# RN821X_RN721X_SOC_V2 register map
File version: v1.0.7
CPU: CM0 r0p0, little endian, no MPU, no FPU, 3 interrupt priority bits
Registers are 32-bit, read-write, reset 0x0 unless marked. A register's access mark holds for its fields unless they carry their own. Offsets are from the block's base; [hi:lo] are bit positions; {n}, {i} and the like mark numbered series; 'fields as' and 'values as' point back to an identical list.

## GPIO
Base 0x50000000
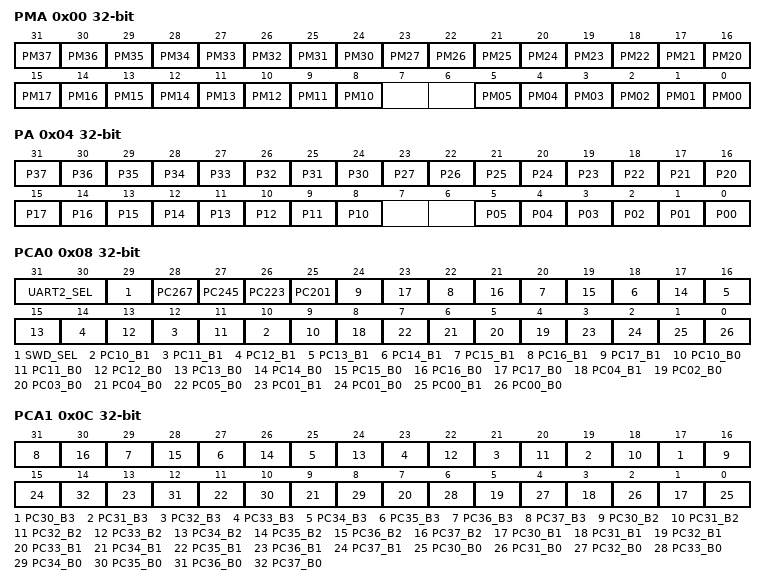
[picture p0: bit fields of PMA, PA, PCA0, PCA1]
0x00 PMA — port A mode register
  [all] fields
    0=OUT (use as output mode); 1=IN (use as input mode)
  [31] PM37 — P37 input(1)/output(0) mode state bi
  [30] PM36 — P36 input(1)/output(0) mode state bit
  [n-6] PM{n} (n=30..35) — P{n} input(1)/output(0) mode selection bit
  [n-4] PM{n} (n=20..27) — P{n} input(1)/output(0) mode selection bit
  [n-2] PM{n} (n=10..17) — P{n} input(1)/output(0) mode selection bit
  [n] PM{n:02} (n=0..5) — P{n:02} input(1)/output(0) mode selection bit
0x04 PA — port A data register
  [31] P37 ro — port A P37 data bit
  [30] P36 ro — port A P36 data bit
  [n-6] P{n} (n=30..35) — port A P{n} data bit
  [n-4] P{n} (n=20..27) — port A P{n} data bit
  [n-2] P{n} (n=10..17) — port A P{n} data bit
  [n] P{n:02} (n=0..5) — port A P{n:02} data bit
0x08 PCA0 — port A mode config register 0
  [31:30] UART2_SEL — UART2 selection bits
    0=PC245 (select P24/P25 as UART2, when P24/P25 PC245 properly cfg as UART2); 1=PC0_1 (select P00/P01 as UART2, when P00/P01 PC00 PC01 properly cfg as UART2); 2=PC223 (select P22/P23 as UART2, when P22/P23 PC223 properly cfg as UART2); 3=PC267 (select P26/P27 as UART2, when P26/P27 PC267 properly cfg as UART2)
  [29] SWD_SEL — SWD selection bit
    0=OTH (when PCA3.PC245(PCA3[20]) = 0, P24 P25 function define by PCA0.PCA0_PC245); 1=P245 (when PCA3.PC245(PCA3[20]) = 0, use P24 as SWDCLK and P25 as SWDIO)
  [28] PC267 — P26 and P27 mode cfg bit
    0=IO (P26 and P27 use as general IO, available when PCA3.PC267(PCA3[27]) = 0); 1=UART3 (P26(RX3) and P27(TX3) use as UART3, available when PCA3.PC267(PCA3[27]) = 0)
  [27] PC245 — P24 and P25 mode cfg bit
    0=IO (P24 and P25 use as general IO, available when PCA3.PC245(PCA3[20]) = 0 and PCA0.SWD_SEL(PCA0[29]) =0); 1=UART2 (P24(RX2) and P25(TX2) use as UART2, available when PCA3.PC245(PCA3[20]) = 0 and PCA0.SWD_SEL(PCA0[29]) =0)
  [26] PC223 — P22 and P23 mode cfg bit
    0=IO (P22 and P23 use as general IO, available when PCA3.PC223(PCA3[13]) = 0); 1=UART1 (P22(RX1) and P23(TX1) use as UART1, available when PCA3.PC223(PCA3[13]) = 0)
  [25] PC201 — P20 and P21 mode cfg bit
    0=IO (P20 and P21 use as general IO, available when PCA3.PC201(PCA3[6]) = 0); 1=UART0 (P20(RX0) and P21(TX0) use as UART0, available when PCA3.PC201(PCA3[6]) = 0)
  [2n-10] PC{n}_B1 (n=10..17) — PC{n} mode cfg bit1, detail info please read manual PCA0.PC{n}(PCA0[{2n-10}:{2n-11}])
  [2n-11] PC{n}_B0 (n=10..17) — PC{n} mode cfg bit0, detail info please read manual PCA0.PC{n}(PCA0[{2n-10}:{2n-11}])
  [8] PC04_B1 — PC04 mode cfg bit1, detail info please read manual PCA0.PC04(PCA0[6])
  [n+2] PC{n:02}_B0 (n=2..5) — PC{n:02} mode cfg bit0, detail info please read manual PCA0.PC{n:02}(PCA0[{n+2}])
  [3] PC01_B1 — PC01 mode cfg bit1, detail info please read manual PCA0.PC01(PCA0[3:2])
  [2] PC01_B0 — PC01 mode cfg bit0, detail info please read manual PCA0.PC01(PCA0[3:2])
  [1] PC00_B1 — PC00 mode cfg bit1, detail info please read manual PCA0.PC00(PCA0[1:0])
  [0] PC00_B0 — PC00 mode cfg bit0, detail info please read manual PCA0.PC00(PCA0[1:0])
0x0C PCA1 — port A mode config register 1
  [2n-43] PC{n}_B3 (n=30..37) — PC{n} mode cfg bit3, detail info please read manual PCA1.PC{n}(PCA1[{2n-59}:{2n-60}])
  [2n-44] PC{n}_B2 (n=30..37) — PC{n} mode cfg bit2, detail info please read manual PCA1.PC{n}(PCA1[{2n-59}:{2n-60}])
  [2n-59] PC{n}_B1 (n=30..37) — PC{n} mode cfg bit1, detail info please read manual PCA1.PC{n}(PCA1[{2n-59}:{2n-60}])
  [2n-60] PC{n}_B0 (n=30..37) — PC{n} mode cfg bit0, detail info please read manual PCA1.PC{n}(PCA1[{2n-59}:{2n-60}])
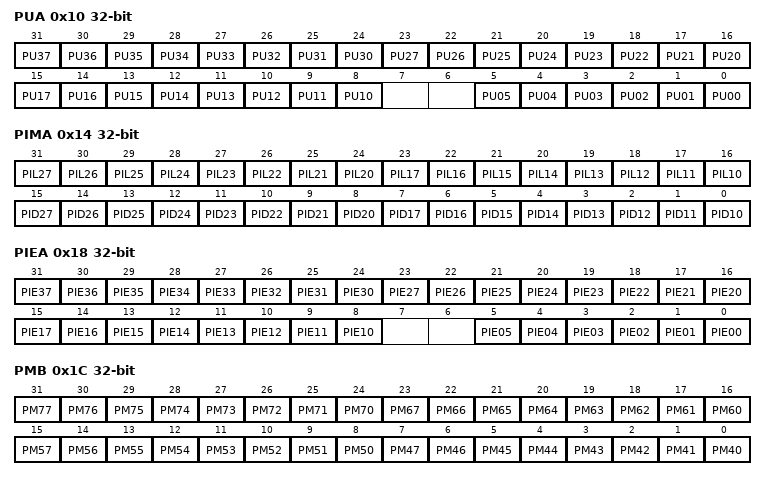
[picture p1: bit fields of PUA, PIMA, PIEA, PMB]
0x10 PUA — port A pull-up config register
  [all] fields
    0=NUL (do not pull-up); 1=PU (pull-up)
  [n-6] PU{n} (n=30..37) — P{n} pull up cfg bit (=0 do not pull up, =1 pull up)
  [n-4] PU{n} (n=20..27) — P{n} pull up cfg bit (=0 do not pull up, =1 pull up)
  [n-2] PU{n} (n=10..17) — P{n} pull up cfg bit (=0 do not pull up, =1 pull up)
  [n] PU{n:02} (n=0..5) — P{n:02} pull up cfg bit (=0 do not pull up, =1 pull up)
0x14 PIMA — port A input config register
  [n+4] PIL{n} (n=20..27) — P{n} input cfg bit
    0=CMOS (select as CMOS input mode, Vil=0.3VCC Vih = 0.7VCC); 1=TTL (select as TTL input mode, Vil=0.16VCC Vih = 0.4VCC)
  [n+6] PIL{n} (n=10..17) — P{n} input cfg bit
    values as PIL20
  [n-12] PID{n} (n=20..27) — P{n} output mode cfg bit
    0=NORM (select as normal output mode); 1=NCH (select as N channel open drain output)
  [n-10] PID{n} (n=10..17) — P{n} output mode cfg bit
    values as PID20
0x18 PIEA — port A input enable register
  [n-6] PIE{n} (n=30..37) — P{n} input disbale bit (=1 disable input, =0 enable input)
  [n-4] PIE{n} (n=20..27) — P{n} input disbale bit (=1 disable input, =0 enable input)
  [n-2] PIE{n} (n=10..17) — P{n} input disbale bit (=1 disable input, =0 enable input)
  [n] PIE{n:02} (n=1..5) — P{n:02} input disbale bit (=1 disable input, =0 enable input)
  [0] PIE00 — P00 input disbale bit (=1 disable input, =0 enable input)
    1=DIS (disable input); 0=EN (enable input)
0x1C PMB — port B mode register
  [n-46] PM{n} (n=70..77) — P{n} input/output cfg bit (=0 output mode, =1 input mode)
  [n-44] PM{n} (n=60..67) — P{n} input/output cfg bit (=0 output mode, =1 input mode)
  [n-42] PM{n} (n=50..57) — P{n} input/output cfg bit (=0 output mode, =1 input mode)
  [n-40] PM{n} (n=41..47) — P{n} input/output cfg bit (=0 output mode, =1 input mode)
  [0] PM40 — P40 input/output cfg bit (=0 output mode, =1 input mode)
    0=OUT (use as output mode); 1=IN (use as input mode)
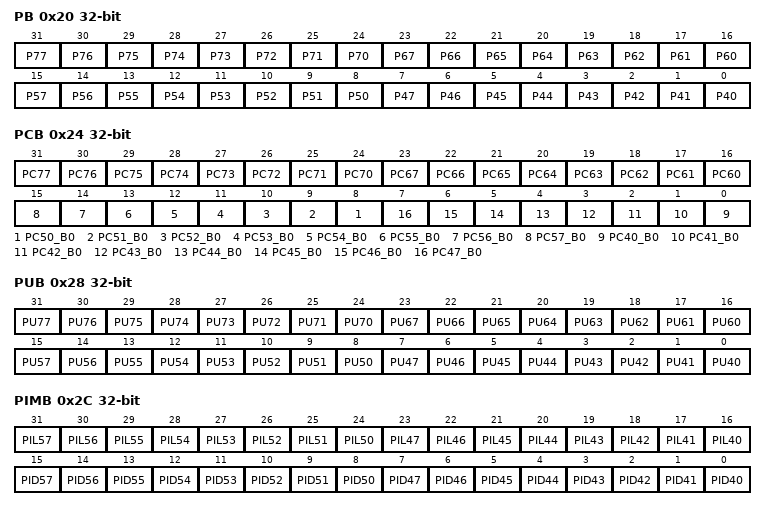
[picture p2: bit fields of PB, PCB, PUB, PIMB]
0x20 PB — port B data register
  [n-46] P{n} (n=70..77) — port B P{n} data bit
  [n-44] P{n} (n=60..67) — port B P{n} data bit
  [n-42] P{n} (n=50..57) — port B P{n} data bit
  [n-40] P{n} (n=40..47) — port B P{n} data bit
0x24 PCB — port B mode config register
  [n-46] PC{n} (n=70..77) — P{n} mode cfg bit
    0=IO (use as general IO); 1=LCD (use as LCD)
  [n-44] PC{n} (n=60..67) — P{n} mode cfg bit
    0=IO (use as general IO); 1=LCD (use as LCD)
  [n-42] PC{n}_B0 (n=50..57) — PC{n} mode cfg bit0, detail info please read manual PCB[{n-42}]
  [n-40] PC{n}_B0 (n=40..47) — PC{n} mode cfg bit0, detail info please read manual PCB[{n-40}]
0x28 PUB — port B pull-up/down config register
  [n-46] PU{n} (n=70..77) — P{n} pull-down enable bit (=1 enable pull-down, =0 do not enable pul down)
    0=NUL (do not pull-down); 1=DOWN (pull-down)
  [n-44] PU{n} (n=60..67) — P{n} pull-down enable bit (=1 enable pull-down, =0 do not enable pul down)
    0=NUL (do not pull-down); 1=DOWN (pull-down)
  [n-42] PU{n} (n=50..57) — P{n} pull-up enable bit (=1 enable pull-up, =0 do not enable pull up)
    0=NUL (do not pull-up); 1=UP (pull-up)
  [n-40] PU{n} (n=40..47) — P{n} pull-up enable bit (=1 enable pull-up, =0 do not enable pull up)
    0=NUL (do not pull-up); 1=UP (pull-up)
0x2C PIMB — port B input config register
  [n-26] PIL{n} (n=50..57) — P{n} input mode cfg bit
    values as PIMA.PIL20
  [n-24] PIL{n} (n=40..47) — P{n} input mode cfg bit
    values as PIMA.PIL20
  [n-42] PID{n} (n=50..57) — P{n} output mode cfg bit
    values as PIMA.PID20
  [n-40] PID{n} (n=40..47) — P{n} output mode cfg bit
    values as PIMA.PID20
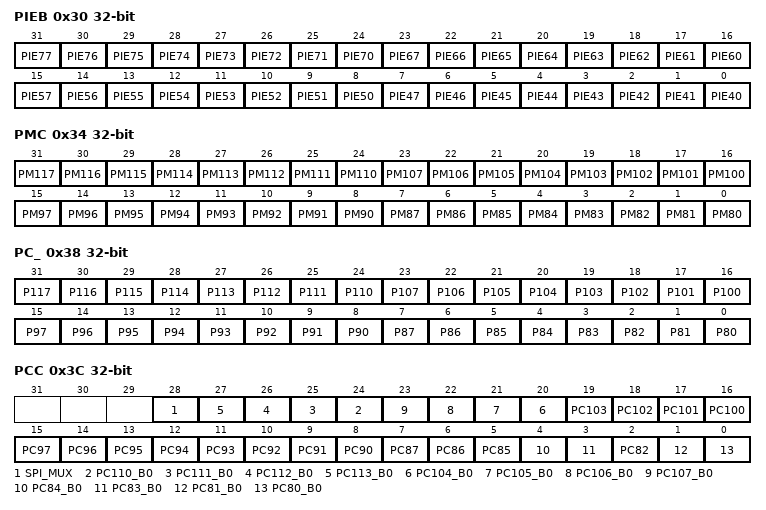
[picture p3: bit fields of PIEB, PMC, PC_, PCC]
0x30 PIEB — port B input enable register
  [all] fields
    1=DIS (do not use as input); 0=EN (use as input)
  [n-46] PIE{n} (n=70..77) — P{n} input disable bit (=1 disable input, =0 enable input)
  [n-44] PIE{n} (n=60..67) — P{n} input disable bit (=1 disable input, =0 enable input)
  [n-42] PIE{n} (n=50..57) — P{n} input disable bit (=1 disable input, =0 enable input)
  [n-40] PIE{n} (n=40..47) — P{n} input disable bit (=1 disable input, =0 enable input)
0x34 PMC — port C mode register
  [all] fields
    0=OUT (use as output mode); 1=IN (use as input mode)
  [n-86] PM{n} (n=110..117) — P{n} input/output cfg bit (=0 output mode, =1 input mode)
  [n-84] PM{n} (n=100..107) — P{n} input/output cfg bit (=0 output mode, =1 input mode)
  [n-82] PM{n} (n=90..97) — P{n} input/output cfg bit (=0 output mode, =1 input mode)
  [n-80] PM{n} (n=80..87) — P{n} input/output cfg bit (=0 output mode, =1 input mode)
0x38 PC_ — port C data register
  [n-86] P{n} (n=110..117) — port C P{n} data bit
  [n-84] P{n} (n=100..107) — port C P{n} data bit
  [n-82] P{n} (n=90..97) — port C P{n} data bit
  [n-80] P{n} (n=80..87) — port C P{n} data bit
0x3C PCC — port C mode config register
  [28] SPI_MUX — SPI0 pin defination bit
    0=P4 (select P50/P51/P46/P47 as SPI0); 1=P11 (select P110/P111/P112/P113 as SPI0)
  [n-86] PC{n}_B0 (n=110..113) — PC{n} mode cfg bit0, detail info please read manual PCC[{n-86}]
  [n-84] PC{n}_B0 (n=104..107) — PC{n} mode cfg bit0, detail info please read manual PCC[{n-84}]
  [n-84] PC{n} (n=100..103) — PC{n} mode cfg bit
    0=IO (select as general IO); 1=LCD (select as LCD)
  [n-82] PC{n} (n=90..97) — PC{n} mode cfg bit
    0=IO (select as general IO); 1=LCD (select as LCD)
  [7] PC87 — PC87 mode cfg bit
    0=IO (select as general IO); 1=LCD (select as LCD)
  [6] PC86 — PC86 mode cfg bit
    0=IO (select as general IO); 1=LCD (select as LCD)
  [5] PC85 — PC85 mode cfg bit
    0=IO (select as general IO); 1=LCD (select as LCD)
  [4] PC84_B0 — PC84 mode cfg bit0, detail info please read manual PCC[4]
  [3] PC83_B0 — PC83 mode cfg bit0, detail info please read manual PCC[3]
  [2] PC82 — PC82 mode cfg bit
    0=IO (select as general IO); 1=LCD (select as LCD)
  [1] PC81_B0 — PC81 mode cfg bit0, detail info please read manual PCC[1]
  [0] PC80_B0 — PC80 mode cfg bit0, detail info please read manual PCC[0]
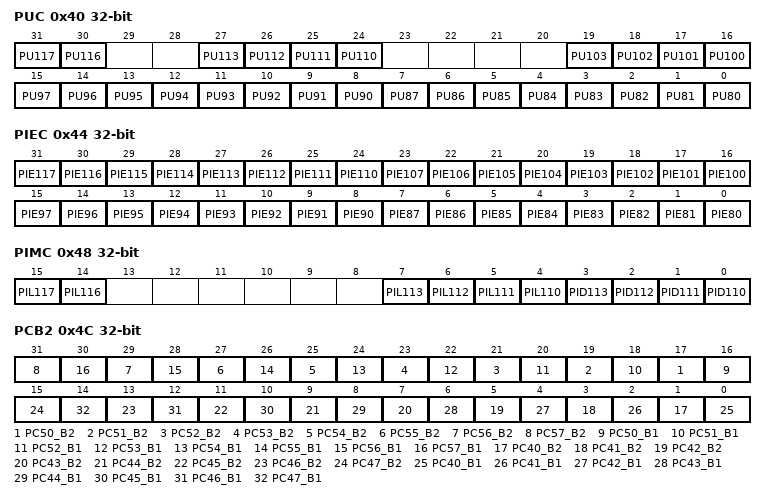
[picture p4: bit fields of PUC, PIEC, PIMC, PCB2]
0x40 PUC — port C pull-up/down config register
  [31] PU117 — P117 pull up enable bit(=1 enable pull-up ,=0 do not enable pull-up)
    0=NUL (do not pull-up); 1=UP (pull-up)
  [30] PU116 — P116 pull up enable bit(=1 enable pull-up ,=0 do not enable pull-up)
    0=NUL (do not pull-up); 1=UP (pull-up)
  [n-86] PU{n} (n=110..113) — P{n} pull up enable bit(=1 enable pull-up ,=0 do not enable pull-up)
    0=NUL (do not pull-up); 1=UP (pull-up)
  [n-84] PU{n} (n=100..103) — P{n} pull down enable bit(=1 enable pull-down ,=0 do not enable pull-down)
    0=NUL (do not pull-up); 1=UP (pull-up)
  [n-82] PU{n} (n=90..97) — P{n} pull down enable bit(=1 enable pull-down ,=0 do not enable pull-down)
    0=NUL (do not pull-down); 1=DOWN (pull-down)
  [n-80] PU{n} (n=80..87) — P{n} pull down enable bit(=1 enable pull-down ,=0 do not enable pull-down)
    0=NUL (do not pull-down); 1=DOWN (pull-down)
0x44 PIEC — port C input enable register
  [all] fields
    1=DIS (disable input); 0=EN (enable input)
  [n-86] PIE{n} (n=110..117) — P{n} input disable bit(=1 disable input, =0 enable input)
  [n-84] PIE{n} (n=100..107) — P{n} input disable bit(=1 disable input, =0 enable input)
  [n-82] PIE{n} (n=90..97) — P{n} input disable bit(=1 disable input, =0 enable input)
  [n-80] PIE{n} (n=80..87) — P{n} input disable bit(=1 disable input, =0 enable input)
0x48 PIMC — port C input config register
  [15] PIL117 — P117 input mode cfg bit
    values as PIMA.PIL20
  [14] PIL116 — P116 input mode cfg bit
    values as PIMA.PIL20
  [n-106] PIL{n} (n=110..113) — P{n} input mode cfg bit
    values as PIMA.PIL20
  [n-110] PID{n} (n=110..113) — P{n} output mode cfg bit
    values as PIMA.PID20
0x4C PCB2 — port B mode config register 2
  [2n-83] PC{n}_B2 (n=50..57) — PC{n} mode cfg bit2, detail info please read manual
  [2n-84] PC{n}_B1 (n=50..57) — PC{n} mode cfg bit1, detail info please read manual
  [2n-79] PC{n}_B2 (n=40..47) — PC{n} mode cfg bit2, detail info please read manual
  [2n-80] PC{n}_B1 (n=40..47) — PC{n} mode cfg bit1, detail info please read manual
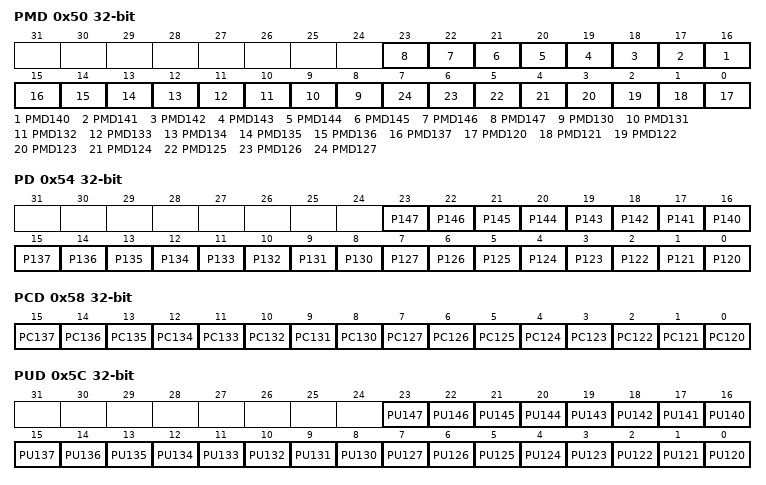
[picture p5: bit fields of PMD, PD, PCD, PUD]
0x50 PMD — port D mode register
  [all] fields
    0=OUT (use as output mode); 1=IN (use as input mode)
  [n-124] PMD{n} (n=140..147) — P{n} input/output mode cfg bit (=0 output mode, =1 input mode)
  [n-122] PMD{n} (n=130..137) — P{n} input/output mode cfg bit (=0 output mode, =1 input mode)
  [n-120] PMD{n} (n=120..127) — P{n} input/output mode cfg bit (=0 output mode, =1 input mode)
0x54 PD — port D data register
  [n-124] P{n} (n=140..147) — port D P{n} data bit
  [n-122] P{n} (n=130..137) — port D P{n} data bit
  [n-120] P{n} (n=120..127) — port D P{n} data bit
0x58 PCD — port D mode config register 0
  [15] PC137 — P137 mode cfg bit (=0 select as IO, =1 reserved)
    0=IO (select as general IO)
  [14] PC136 — P136 mode cfg bit
    0=IO (select as general IO)
  [13] PC135 — P135 mode cfg bit
    0=IO (select as general IO); 1=LCDVP2 (select as LCDVP2)
  [12] PC134 — P134 mode cfg bit
    0=IO (select as general IO); 1=LCDVP1 (select as LCDVP1)
  [11] PC133 — P133 mode cfg bit (=0 select as IO, =1 reserved)
    0=IO (select as general IO)
  [10] PC132 — P132 mode cfg bit
    0=IO (select as general IO); 1=LCDVC (select as LCDVC)
  [9] PC131 — P131 mode cfg bit
    0=IO (select as general IO); 1=LCDVB (select as LCDVB)
  [8] PC130 — P130 mode cfg bit
    0=IO (select as general IO); 1=LCDVA (select as LCDVA)
  [n-120] PC{n} (n=120..127) — P{n} mode cfg bit
    0=IO (select as general IO); 1=LCD (select as LCD)
0x5C PUD — port D pull-up/down config register
  [n-124] PU{n} (n=140..147) — P{n} pull up enable bit(=1 enable pull-up ,=0 do not enable pull-up)
    0=NUL (do not pull-up); 1=UP (pull-up)
  [n-122] PU{n} (n=130..137) — P{n} pull down enable bit(=1 enable pull-down ,=0 do not enable pull-down)
    0=NUL (do not pull-down); 1=DOWN (pull-down)
  [n-120] PU{n} (n=120..127) — P{n} pull down enable bit(=1 enable pull-down ,=0 do not enable pull-down)
    0=NUL (do not pull-down); 1=DOWN (pull-down)
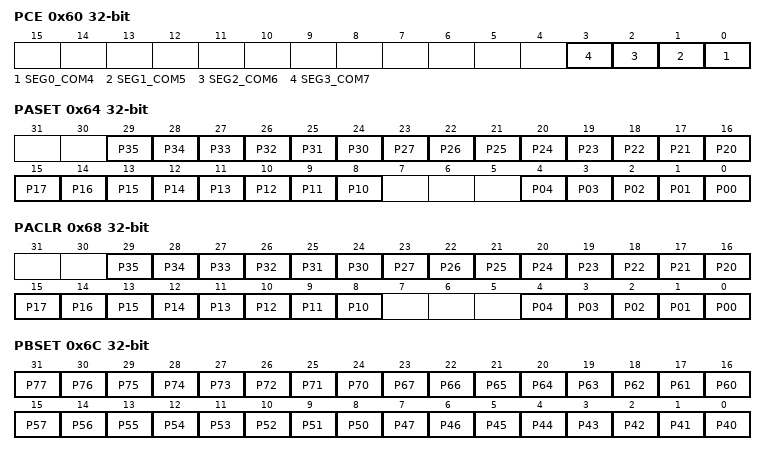
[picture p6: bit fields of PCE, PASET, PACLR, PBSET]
0x60 PCE — SEGCOM mode selection register
  [all] fields
    0=SEG (select as SEG); 1=COM (select as COM)
  [n] SEG{n}_COM{n+4} (n=0..3) — SEG{n}_COM{n+4} mode selection bit
0x64 PASET — port A state set register
  [all] fields
    0=NUL (no effection); 1=HIGH (set as high level)
  [n-6] P{n} (n=30..35) — PA P{n} state set bit
  [n-4] P{n} (n=20..27) — PA P{n} state set bit
  [n-2] P{n} (n=10..17) — PA P{n} state set bit
  [n] P{n:02} (n=0..4) — PA P{n:02} state set bit
0x68 PACLR — port A state clean register
  [all] fields
    0=NUL (no effection); 1=CLR (clean pin state, set low level output)
  [n-6] P{n} (n=30..35) — PA P{n} state clean bit
  [n-4] P{n} (n=20..27) — PA P{n} state clean bit
  [n-2] P{n} (n=10..17) — PA P{n} state clean bit
  [n] P{n:02} (n=0..4) — PA P{n:02} state clean bit
0x6C PBSET — port B state set register
  [all] fields
    0=NUL (no effection); 1=HIGH (set as high level)
  [n-46] P{n} (n=70..77) — PB P{n} state set bit
  [n-44] P{n} (n=60..67) — PB P{n} state set bit
  [n-42] P{n} (n=50..57) — PB P{n} state set bit
  [n-40] P{n} (n=40..47) — PB P{n} state set bit
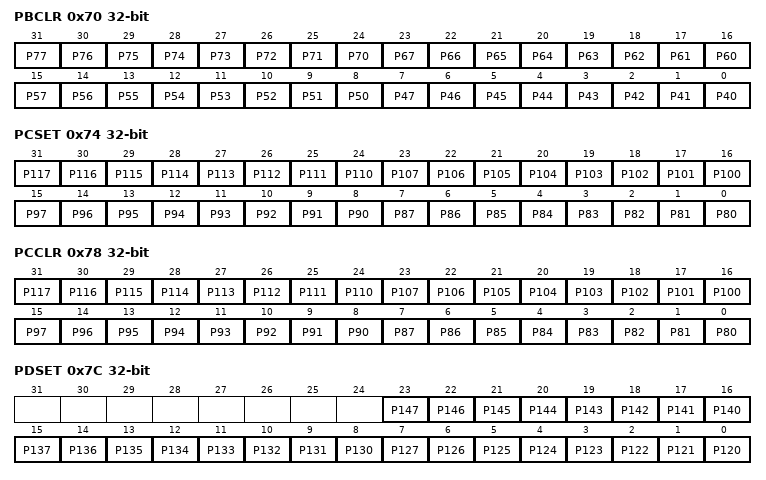
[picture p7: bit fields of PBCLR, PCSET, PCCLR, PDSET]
0x70 PBCLR — port B state clean register
  [all] fields
    values as the fields of PACLR
  [n-46] P{n} (n=70..77) — PB P{n} state clean bit
  [n-44] P{n} (n=60..67) — PB P{n} state clean bit
  [n-42] P{n} (n=50..57) — PB P{n} state clean bit
  [n-40] P{n} (n=40..47) — PB P{n} state clean bit
0x74 PCSET — port C state set register
  [all] fields
    0=NUL (no effection); 1=HIGH (set as high level)
  [n-86] P{n} (n=110..117) — PC P{n} state set bit
  [n-84] P{n} (n=100..107) — PC P{n} state set bit
  [n-82] P{n} (n=90..97) — PC P{n} state set bit
  [n-80] P{n} (n=80..87) — PC P{n} state set bit
0x78 PCCLR — port C state clean register
  [all] fields
    values as the fields of PACLR
  [n-86] P{n} (n=110..117) — PC P{n} state clean bit
  [n-84] P{n} (n=100..107) — PC P{n} state clean bit
  [n-82] P{n} (n=90..97) — PC P{n} state clean bit
  [n-80] P{n} (n=80..87) — PC P{n} state clean bit
0x7C PDSET — port D state set register
  [all] fields
    0=NUL (no effection); 1=HIGH (set as high level)
  [n-124] P{n} (n=140..147) — PD P{n} state set bit
  [n-122] P{n} (n=130..137) — PD P{n} state set bit
  [n-120] P{n} (n=120..127) — PD P{n} state set bit
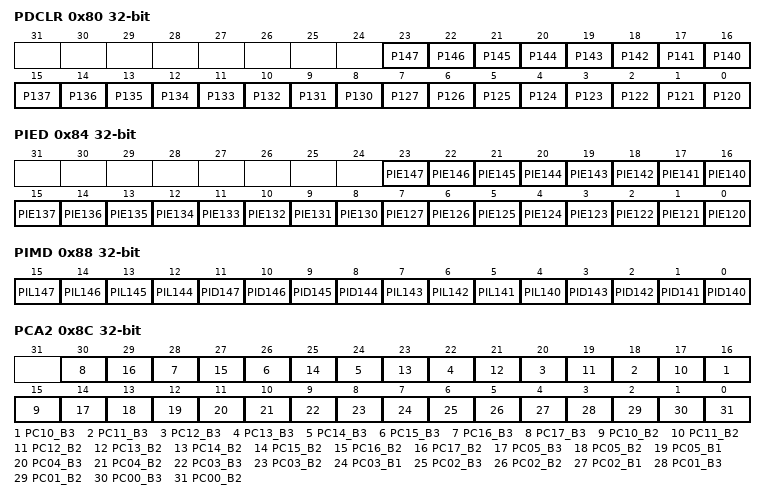
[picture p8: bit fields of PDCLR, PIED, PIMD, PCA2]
0x80 PDCLR — port D state clean register
  [all] fields
    values as the fields of PACLR
  [n-124] P{n} (n=140..147) — PD P{n} state clean bit
  [n-122] P{n} (n=130..137) — PD P{n} state clean bit
  [n-120] P{n} (n=120..127) — PD P{n} state clean bit
0x84 PIED — port D input enable register
  [all] fields
    1=DIS (disable input); 0=EN (enable input)
  [n-124] PIE{n} (n=140..147) — P{n} input disable bit
  [n-122] PIE{n} (n=130..137) — P{n} input disable bit
  [n-120] PIE{n} (n=120..127) — P{n} input disable bit
0x88 PIMD — port D input config register
  [n-132] PIL{n} (n=144..147) — P{n} input mode cfg bit
  [n-136] PID{n} (n=144..147) — P{n} output mode cfg bit
  [7] PIL143 — P143 input mode cfg bit
  [6] PIL142 — P142 input mode cfg bit
    values as PIMA.PIL20
  [5] PIL141 — P141 input mode cfg bit
    values as PIMA.PIL20
  [4] PIL140 — P140 input mode cfg bit
    values as PIMA.PIL20
  [3] PID143 — P143 output mode cfg bit
    0=NORM (select as normal output mode)
  [2] PID142 — P142 output mode cfg bit
    values as PIMA.PID20
  [1] PID141 — P141 output mode cfg bit
    values as PIMA.PID20
  [0] PID140 — P140 output mode cfg bit
    values as PIMA.PID20
0x8C PCA2 — port A mode config register 2
  [2n-4] PC{n}_B3 (n=10..17) — PC{n} mode cfg bit3, detail info please read manual PCA0.PC{n}(PCA0[{2n-10}:{2n-11}])
  [2n-5] PC{n}_B2 (n=10..17) — PC{n} mode cfg bit2, detail info please read manual PCA0.PC{n}(PCA0[{2n-10}:{2n-11}])
  [14] PC05_B3 — PC05 mode cfg bit3, detail info please read manual PCA0.PC05(PCA0[7])
  [13] PC05_B2 — PC05 mode cfg bit2, detail info please read manual PCA0.PC05(PCA0[7])
  [12] PC05_B1 — PC05 mode cfg bit1, detail info please read manual PCA0.PC05(PCA0[7])
  [11] PC04_B3 — PC04 mode cfg bit3, detail info please read manual PCA0.PC04(PCA0[6])
  [10] PC04_B2 — PC04 mode cfg bit2, detail info please read manual PCA0.PC04(PCA0[6])
  [9] PC03_B3 — PC03 mode cfg bit3, detail info please read manual PCA0.PC03(PCA0[5])
  [8] PC03_B2 — PC03 mode cfg bit2, detail info please read manual PCA0.PC03(PCA0[5])
  [7] PC03_B1 — PC03 mode cfg bit1, detail info please read manual PCA0.PC03(PCA0[5])
  [6] PC02_B3 — PC02 mode cfg bit3, detail info please read manual PCA0.PC02(PCA0[4])
  [5] PC02_B2 — PC02 mode cfg bit2, detail info please read manual PCA0.PC02(PCA0[4])
  [4] PC02_B1 — PC02 mode cfg bit1, detail info please read manual PCA0.PC02(PCA0[4])
  [3] PC01_B3 — PC01 mode cfg bit3, detail info please read manual PCA0.PC01(PCA0[3:2])
  [2] PC01_B2 — PC01 mode cfg bit2, detail info please read manual PCA0.PC01(PCA0[3:2])
  [1] PC00_B3 — PC00 mode cfg bit3, detail info please read manual PCA0.PC00(PCA0[1:0])
  [0] PC00_B2 — PC00 mode cfg bit2, detail info please read manual PCA0.PC00(PCA0[1:0])
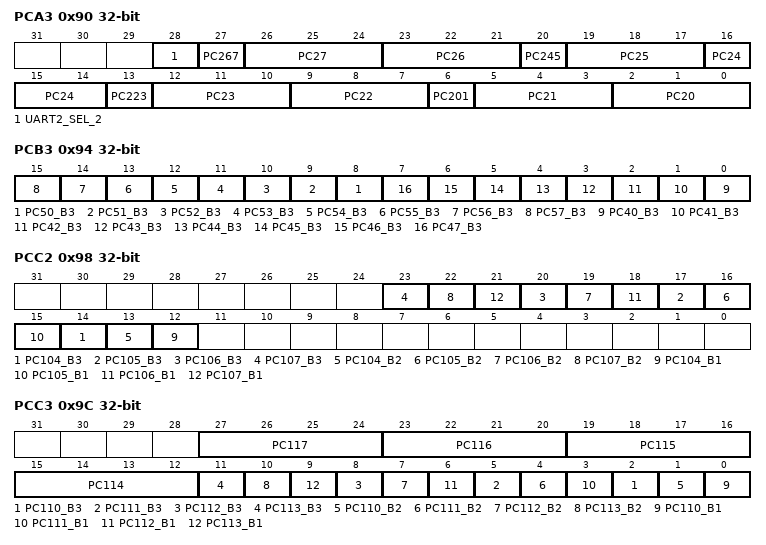
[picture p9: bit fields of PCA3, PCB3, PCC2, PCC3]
0x90 PCA3 — port A mode config register 3
  [28] UART2_SEL_2 — UART2 second selection bit, detail info please read manual PCA0[31:30]
  [27] PC267 — PC267 second mode cfg bit
  [26:24] PC27 — PC27 second mode cfg bits
  [23:21] PC26 — PC26 second mode cfg bits
  [20] PC245 — PC245 second mode cfg bit
  [19:17] PC25 — PC25 second mode cfg bits
  [16:14] PC24 — PC24 second mode cfg bits
  [13] PC223 — PC223 second mode cfg bit
  [12:10] PC23 — PC23 second mode cfg bits
  [9:7] PC22 — PC22 second mode cfg bits
  [6] PC201 — PC201 second mode cfg bit
  [5:3] PC21 — PC21 second mode cfg bits
  [2:0] PC20 — PC20 second mode cfg bits
0x94 PCB3 — port B mode config register 3
  [n-42] PC{n}_B3 (n=50..57) — PC{n} mode cfg bit3, detail info please read manual PC{n}[{n-42}]
  [n-40] PC{n}_B3 (n=40..47) — PC{n} mode cfg bit3, detail info please read manual PC{n}[{n-40}]
0x98 PCC2 — port C mode config register 2
  [3n-298] PC{n}_B3 (n=104..107) — PC{n} mode cfg bit3, detail info please read manual PCC[{n-84}]
  [3n-299] PC{n}_B2 (n=104..107) — PC{n} mode cfg bit2, detail info please read manual PCC[{n-84}]
  [3n-300] PC{n}_B1 (n=104..107) — PC{n} mode cfg bit1, detail info please read manual PCC[{n-84}]
0x9C PCC3 — port C mode config register 3
  [27:24] PC117 — PC117 mode cfg bits
    0=IO (select as general IO); 1=RTC1S (select as perpetual calendar second output)
  [23:20] PC116 — PC116 mode cfg bits
    0=IO (select as general IO); 1=AIN6 (select as analog input AIN6)
  [19:16] PC115 — PC115 mode cfg bits
    0=IO (select as general IO(only input)); 2=IA_IN (select as IA_IN)
  [15:12] PC114 — PC114 mode cfg bits
    0=IO (select as general IO); 1=IA_IN (select as IA_IN)
  [3n-328] PC{n}_B3 (n=110..113) — PC{n} mode cfg bit3, detail info please read manual PCC[{n-86}]
  [3n-329] PC{n}_B2 (n=110..113) — PC{n} mode cfg bit2, detail info please read manual PCC[{n-86}]
  [3n-330] PC{n}_B1 (n=110..113) — PC{n} mode cfg bit1, detail info please read manual PCC[{n-86}]
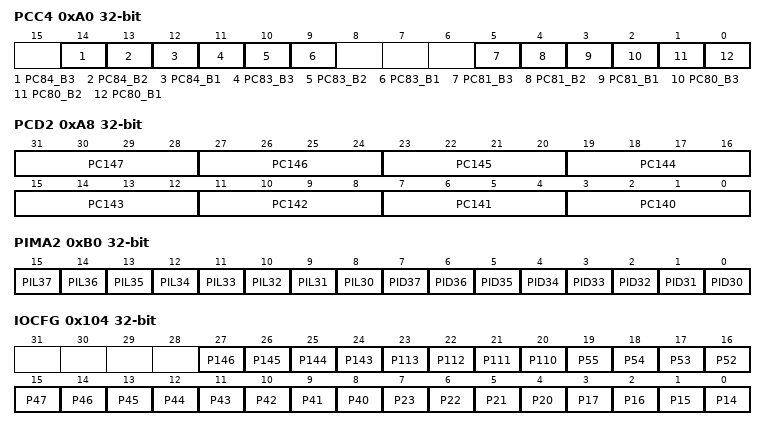
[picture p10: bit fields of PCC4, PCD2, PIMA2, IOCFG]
0xA0 PCC4 — port C mode config register 4
  [14] PC84_B3 — PC84 mode cfg bit3, detail info please read manual PCC[4]
  [13] PC84_B2 — PC84 mode cfg bit2, detail info please read manual PCC[4]
  [12] PC84_B1 — PC84 mode cfg bit1, detail info please read manual PCC[4]
  [11] PC83_B3 — PC83 mode cfg bit3, detail info please read manual PCC[3]
  [10] PC83_B2 — PC83 mode cfg bit2, detail info please read manual PCC[3]
  [9] PC83_B1 — PC83 mode cfg bit1, detail info please read manual PCC[3]
  [5] PC81_B3 — PC81 mode cfg bit3, detail info please read manual PCC[1]
  [4] PC81_B2 — PC81 mode cfg bit2, detail info please read manual PCC[1]
  [3] PC81_B1 — PC81 mode cfg bit1, detail info please read manual PCC[1]
  [2] PC80_B3 — PC80 mode cfg bit3, detail info please read manual PCC[0]
  [1] PC80_B2 — PC80 mode cfg bit2, detail info please read manual PCC[0]
  [0] PC80_B1 — PC80 mode cfg bit1, detail info please read manual PCC[0]
0xA8 PCD2 — port D mode config register 2
  [31:28] PC147 — PC147 mode cfg bits
    values as PCC3.PC117
  [27:24] PC146 — PC146 mode cfg bits
    0=IO (select as general IO); 1=ADC_CLKO (select as ADC_CLKO); 2=TRIG_OUT (select as TRIG_OUT); 3=SPI2_MOSI (select as SPI2_MOSI)
  [23:20] PC145 — PC145 mode cfg bits
    0=IO (select as general IO); 1=ADC_CLKO (select as ADC_CLKO); 2=TRIG_OUT (select as TRIG_OUT); 3=SPI2_MISO (select as SPI2_MISO)
  [19:16] PC144 — PC144 mode cfg bits
    0=IO (select as general IO); 1=ADC_CLKO (select as ADC_CLKO); 2=TRIG_OUT (select as TRIG_OUT); 3=SPI2_SCLK (select as SPI2_SCLK)
  [15:12] PC143 — PC143 mode cfg bits
    0=IO (select as general IO); 1=ADC_CLKO (select as ADC_CLKO); 2=TRIG_OUT (select as TRIG_OUT); 3=SPI2_SCSN (select as SPI2_SCSN)
  [11:8] PC142 — PC142 mode cfg bits
    0=IO (select as general IO); 1=ADC_CLKO (select as ADC_CLKO); 2=TRIG_OUT (select as TRIG_OUT); 3=RTC1S (select as perpetual calendar second output)
  [7:4] PC141 — PC141 mode cfg bits
    values as PC142
  [3:0] PC140 — PC140 mode cfg bits
    values as PC142
0xB0 PIMA2 — port A input config register 2
  [n-22] PIL{n} (n=30..37) — P{n} input mode cfg bit
    values as PIMA.PIL20
  [n-30] PID{n} (n=30..37) — P{n} output mode cfg bit
    values as PIMA.PID20
0x100 LURT_CFG — LPUART config register
  [2:0] LURT_CFG — LPUART and UARTx IO cfg bits
    0=NUL (do not use LPUART); {v}=UART{v-1} (LPUART use UART{v-1} IO) (v=1..6)
0x104 IOCFG — IO congfig register
  [n-119] P{n} (n=143..146) — P{n} IO driving capability select bit
  [n-90] P{n} (n=110..113) — P{n} IO driving capability select bit
  [n-36] P{n} (n=52..55) — P{n} IO driving capability select bit
  [n-32] P{n} (n=40..47) — P{n} IO driving capability select bit
  [n-16] P{n} (n=20..23) — P{n} IO driving capability select bit
  [3] P17 — P17 IO driving capability select bit
  [2] P16 — P16 IO driving capability select bit
  [1] P15 — P15 IO driving capability select bit
  [0] P14 — P14 IO driving capability select bit
    1=FAST (select as slew rate fast mode, have driving capability of 3mA); 0=SLOW (select as slew rate slow mode, have driving capability of 1.5mA)
